VERSION "J35_6MT"

NS_ :

BS_:

BU_: PCM UNKNOWN VSA

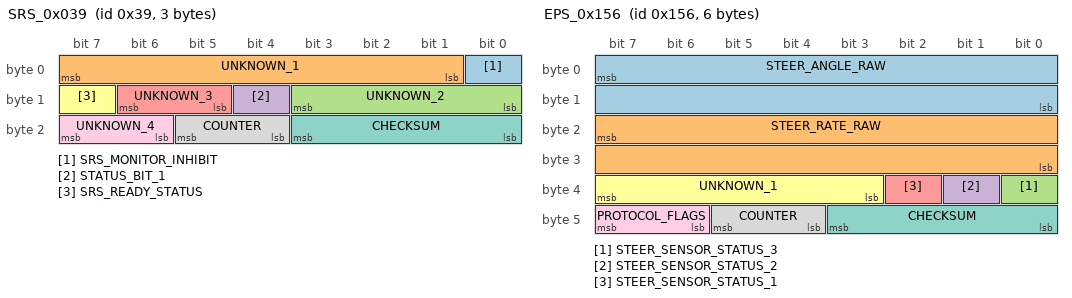
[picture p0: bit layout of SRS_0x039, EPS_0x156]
BO_ 57 SRS_0x039: 3 UNKNOWN
 SG_ SRS_MONITOR_INHIBIT : 0|1@1+ (1,0) [0|1] ""  PCM
 SG_ UNKNOWN_1 : 1|7@1+ (1,0) [0|127] ""  PCM
 SG_ UNKNOWN_2 : 8|4@1+ (1,0) [0|15] ""  PCM
 SG_ STATUS_BIT_1 : 12|1@1+ (1,0) [0|1] ""  PCM
 SG_ UNKNOWN_3 : 13|2@1+ (1,0) [0|3] ""  PCM
 SG_ SRS_READY_STATUS : 15|1@1+ (1,0) [0|1] ""  PCM
 SG_ CHECKSUM : 16|4@1+ (1,0) [0|15] ""  PCM
 SG_ COUNTER : 20|2@1+ (1,0) [0|3] ""  PCM
 SG_ UNKNOWN_4 : 22|2@1+ (1,0) [0|3] ""  PCM

BO_ 342 EPS_0x156: 6 UNKNOWN
 SG_ STEER_ANGLE_RAW : 7|16@0- (-0.1,0) [-3276.7000000000003|3276.8] "deg"  UNKNOWN
 SG_ STEER_RATE_RAW : 23|16@0- (-1,0) [-32767|32768] "deg/s"  UNKNOWN
 SG_ STEER_SENSOR_STATUS_3 : 32|1@1+ (1,0) [0|1] ""  UNKNOWN
 SG_ STEER_SENSOR_STATUS_2 : 33|1@1+ (1,0) [0|1] ""  UNKNOWN
 SG_ STEER_SENSOR_STATUS_1 : 34|1@1+ (1,0) [0|1] ""  UNKNOWN
 SG_ UNKNOWN_1 : 35|5@1+ (1,0) [0|31] ""  UNKNOWN
 SG_ CHECKSUM : 40|4@1+ (1,0) [0|15] ""  UNKNOWN
 SG_ COUNTER : 44|2@1+ (1,0) [0|3] ""  UNKNOWN
 SG_ PROTOCOL_FLAGS : 46|2@1+ (1,0) [0|3] ""  UNKNOWN

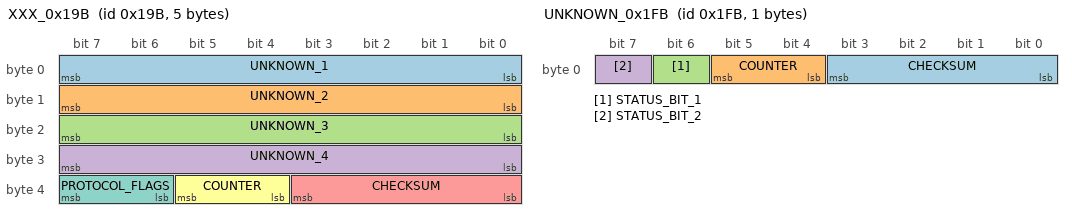
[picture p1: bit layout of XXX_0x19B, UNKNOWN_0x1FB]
BO_ 411 XXX_0x19B: 5 UNKNOWN
 SG_ UNKNOWN_1 : 0|8@1+ (1,0) [0|255] ""  UNKNOWN
 SG_ UNKNOWN_2 : 8|8@1+ (1,0) [0|255] ""  UNKNOWN
 SG_ UNKNOWN_3 : 16|8@1+ (1,0) [0|255] ""  UNKNOWN
 SG_ UNKNOWN_4 : 24|8@1+ (1,0) [0|255] ""  UNKNOWN
 SG_ CHECKSUM : 32|4@1+ (1,0) [0|15] ""  UNKNOWN
 SG_ COUNTER : 36|2@1+ (1,0) [0|3] ""  UNKNOWN
 SG_ PROTOCOL_FLAGS : 38|2@1+ (1,0) [0|3] ""  UNKNOWN

BO_ 506 UNKNOWN_0x1FA: 8 UNKNOWN
 SG_ BRAKE_COMMAND_RAW_TBD : 7|10@0+ (1,0) [0|1023] ""  VSA
 SG_ UNKNOWN_1 : 8|3@1+ (1,0) [0|7] ""  PCM
 SG_ UNKNOWN_2 : 11|2@1+ (1,0) [0|3] ""  PCM
 SG_ STATUS_BIT_1 : 13|1@1+ (1,0) [0|1] ""  PCM
 SG_ STATUS_BIT_2 : 16|1@1+ (1,0) [0|1] ""  PCM
 SG_ STATUS_BIT_3 : 17|1@1+ (1,0) [0|1] ""  PCM
 SG_ STATUS_BIT_4 : 18|1@1+ (1,0) [0|1] ""  PCM
 SG_ STATUS_BIT_5 : 19|1@1+ (1,0) [0|1] ""  PCM
 SG_ CRUISE_BRAKE_STATE_TBD : 20|2@1+ (1,0) [0|3] ""  PCM
 SG_ STATUS_BIT_6 : 22|1@1+ (1,0) [0|1] ""  PCM
 SG_ STATUS_BIT_7 : 23|1@1+ (1,0) [0|1] ""  PCM
 SG_ UNKNOWN_3 : 24|4@1+ (1,0) [0|15] ""  PCM
 SG_ STATUS_BIT_8 : 28|1@1+ (1,0) [0|1] ""  PCM
 SG_ STATUS_BIT_9 : 29|1@1+ (1,0) [0|1] ""  PCM
 SG_ STATUS_BIT_10 : 30|1@1+ (1,0) [0|1] ""  PCM
 SG_ STATUS_BIT_11 : 31|1@1+ (1,0) [0|1] ""  PCM
 SG_ CRUISE_STATUS_TBD : 32|3@1+ (1,0) [0|7] ""  PCM
 SG_ STATUS_BIT_12 : 35|1@1+ (1,0) [0|1] ""  PCM
 SG_ STATUS_BIT_13 : 36|1@1+ (1,0) [0|1] ""  PCM
 SG_ CRUISE_STATE_TBD : 37|2@1+ (1,0) [0|3] ""  PCM
 SG_ STATUS_BIT_14 : 39|1@1+ (1,0) [0|1] ""  PCM
 SG_ UNKNOWN_4 : 40|8@1+ (1,0) [0|255] ""  PCM
 SG_ UNKNOWN_5 : 55|10@0+ (1,0) [0|1023] ""  PCM
 SG_ CHECKSUM : 56|4@1+ (1,0) [0|15] ""  PCM
 SG_ COUNTER : 60|2@1+ (1,0) [0|3] ""  PCM

BO_ 507 UNKNOWN_0x1FB: 1 UNKNOWN
 SG_ CHECKSUM : 0|4@1+ (1,0) [0|15] ""  PCM
 SG_ COUNTER : 4|2@1+ (1,0) [0|3] ""  PCM
 SG_ STATUS_BIT_1 : 6|1@1+ (1,0) [0|1] ""  PCM
 SG_ STATUS_BIT_2 : 7|1@1+ (1,0) [0|1] ""  PCM

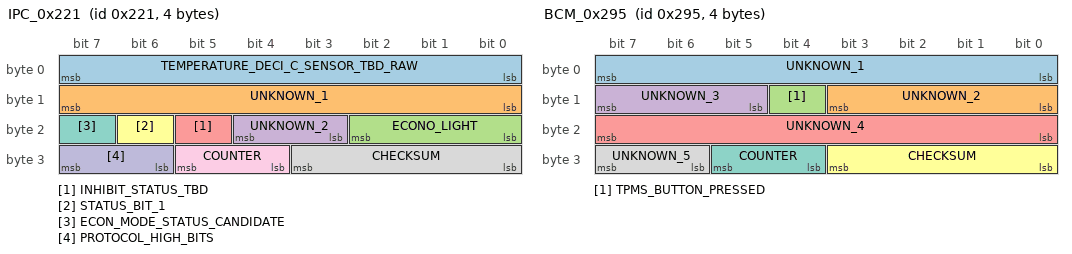
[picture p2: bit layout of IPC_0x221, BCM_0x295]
BO_ 545 IPC_0x221: 4 UNKNOWN
 SG_ TEMPERATURE_DECI_C_SENSOR_TBD_RAW : 0|8@1+ (1,-30) [-30|225] "degC"  PCM
 SG_ UNKNOWN_1 : 8|8@1+ (1,0) [0|255] ""  PCM
 SG_ ECONO_LIGHT : 16|3@1+ (1,0) [0|7] ""  PCM
 SG_ UNKNOWN_2 : 19|2@1+ (1,0) [0|3] ""  PCM
 SG_ INHIBIT_STATUS_TBD : 21|1@1+ (1,0) [0|1] ""  PCM
 SG_ STATUS_BIT_1 : 22|1@1+ (1,0) [0|1] ""  PCM
 SG_ ECON_MODE_STATUS_CANDIDATE : 23|1@1+ (1,0) [0|1] ""  PCM
 SG_ CHECKSUM : 24|4@1+ (1,0) [0|15] ""  PCM
 SG_ COUNTER : 28|2@1+ (1,0) [0|3] ""  PCM
 SG_ PROTOCOL_HIGH_BITS : 30|2@1+ (1,0) [0|3] ""  PCM
VAL_ 545 ECONO_LIGHT 0 "OFF" 3 "ON" ;

BO_ 661 BCM_0x295: 4 UNKNOWN
 SG_ UNKNOWN_1 : 0|8@1+ (1,0) [0|255] ""  UNKNOWN
 SG_ UNKNOWN_2 : 8|4@1+ (1,0) [0|15] ""  UNKNOWN
 SG_ TPMS_BUTTON_PRESSED : 12|1@1+ (1,0) [0|1] ""  UNKNOWN
 SG_ UNKNOWN_3 : 13|3@1+ (1,0) [0|7] ""  UNKNOWN
 SG_ UNKNOWN_4 : 16|8@1+ (1,0) [0|255] ""  UNKNOWN
 SG_ CHECKSUM : 24|4@1+ (1,0) [0|15] ""  UNKNOWN
 SG_ COUNTER : 28|2@1+ (1,0) [0|3] ""  UNKNOWN
 SG_ UNKNOWN_5 : 30|2@1+ (1,0) [0|3] ""  UNKNOWN

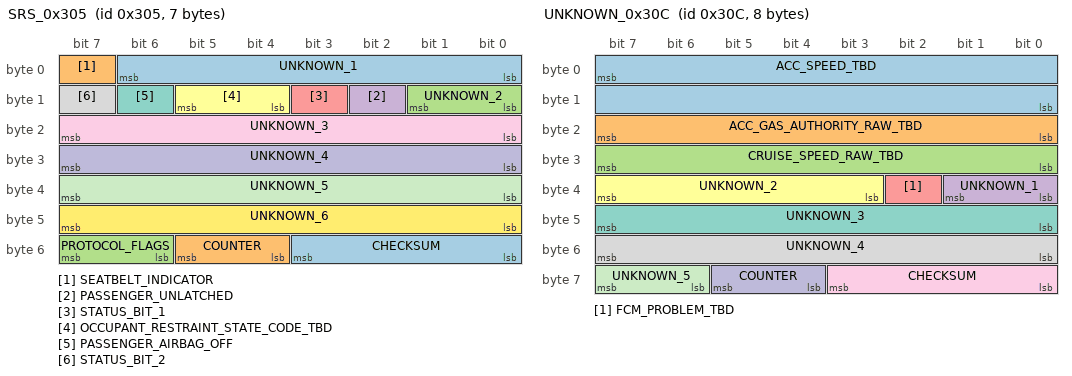
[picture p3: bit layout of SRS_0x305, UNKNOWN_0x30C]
BO_ 773 SRS_0x305: 7 UNKNOWN
 SG_ UNKNOWN_1 : 0|7@1+ (1,0) [0|127] ""  PCM
 SG_ SEATBELT_INDICATOR : 7|1@1+ (1,0) [0|1] ""  PCM
 SG_ UNKNOWN_2 : 8|2@1+ (1,0) [0|3] ""  PCM
 SG_ PASSENGER_UNLATCHED : 10|1@1+ (1,0) [0|1] ""  PCM
 SG_ STATUS_BIT_1 : 11|1@1+ (1,0) [0|1] ""  PCM
 SG_ OCCUPANT_RESTRAINT_STATE_CODE_TBD : 12|2@1+ (1,0) [0|0] ""  PCM
 SG_ PASSENGER_AIRBAG_OFF : 14|1@1+ (1,0) [0|1] ""  PCM
 SG_ STATUS_BIT_2 : 15|1@1+ (1,0) [0|1] ""  PCM
 SG_ UNKNOWN_3 : 16|8@1+ (1,0) [0|255] ""  PCM
 SG_ UNKNOWN_4 : 24|8@1+ (1,0) [0|255] ""  PCM
 SG_ UNKNOWN_5 : 32|8@1+ (1,0) [0|255] ""  PCM
 SG_ UNKNOWN_6 : 40|8@1+ (1,0) [0|255] ""  PCM
 SG_ CHECKSUM : 48|4@1+ (1,0) [0|15] ""  PCM
 SG_ COUNTER : 52|2@1+ (1,0) [0|3] ""  PCM
 SG_ PROTOCOL_FLAGS : 54|2@1+ (1,0) [0|3] ""  PCM

BO_ 780 UNKNOWN_0x30C: 8 UNKNOWN
 SG_ ACC_SPEED_TBD : 7|16@0+ (0.01,0) [0.0|655.35] "km/h"  PCM
 SG_ ACC_GAS_AUTHORITY_RAW_TBD : 16|8@1+ (5,0) [0|1275] ""  PCM
 SG_ CRUISE_SPEED_RAW_TBD : 24|8@1+ (1,0) [0|255] ""  PCM
 SG_ UNKNOWN_1 : 32|2@1+ (1,0) [0|3] ""  PCM
 SG_ FCM_PROBLEM_TBD : 34|1@1+ (1,0) [0|1] ""  PCM
 SG_ UNKNOWN_2 : 35|5@1+ (1,0) [0|31] ""  PCM
 SG_ UNKNOWN_3 : 40|8@1+ (1,0) [0|255] ""  PCM
 SG_ UNKNOWN_4 : 48|8@1+ (1,0) [0|255] ""  PCM
 SG_ CHECKSUM : 56|4@1+ (1,0) [0|15] ""  PCM
 SG_ COUNTER : 60|2@1+ (1,0) [0|3] ""  PCM
 SG_ UNKNOWN_5 : 62|2@1+ (1,0) [0|3] ""  PCM

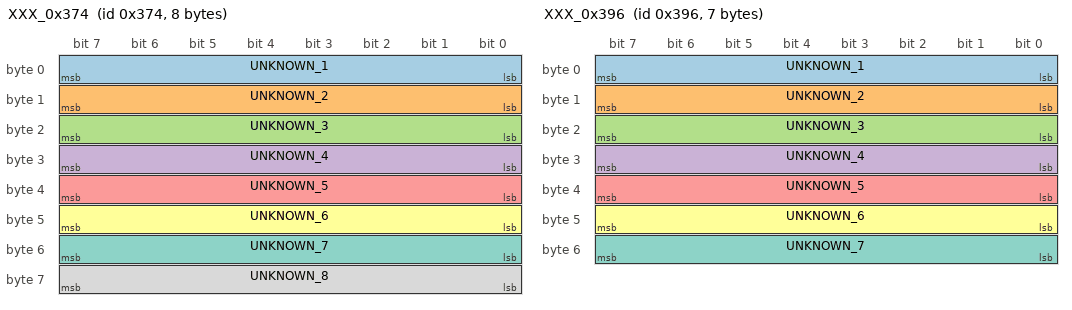
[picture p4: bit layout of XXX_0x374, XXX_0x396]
BO_ 884 XXX_0x374: 8 UNKNOWN
 SG_ UNKNOWN_1 : 0|8@1+ (1,0) [0|255] ""  UNKNOWN
 SG_ UNKNOWN_2 : 8|8@1+ (1,0) [0|255] ""  UNKNOWN
 SG_ UNKNOWN_3 : 16|8@1+ (1,0) [0|255] ""  UNKNOWN
 SG_ UNKNOWN_4 : 24|8@1+ (1,0) [0|255] ""  UNKNOWN
 SG_ UNKNOWN_5 : 32|8@1+ (1,0) [0|255] ""  UNKNOWN
 SG_ UNKNOWN_6 : 40|8@1+ (1,0) [0|255] ""  UNKNOWN
 SG_ UNKNOWN_7 : 48|8@1+ (1,0) [0|255] ""  UNKNOWN
 SG_ UNKNOWN_8 : 56|8@1+ (1,0) [0|255] ""  UNKNOWN

BO_ 918 XXX_0x396: 7 UNKNOWN
 SG_ UNKNOWN_1 : 0|8@1+ (1,0) [0|255] ""  UNKNOWN
 SG_ UNKNOWN_2 : 8|8@1+ (1,0) [0|255] ""  UNKNOWN
 SG_ UNKNOWN_3 : 16|8@1+ (1,0) [0|255] ""  UNKNOWN
 SG_ UNKNOWN_4 : 24|8@1+ (1,0) [0|255] ""  UNKNOWN
 SG_ UNKNOWN_5 : 32|8@1+ (1,0) [0|255] ""  UNKNOWN
 SG_ UNKNOWN_6 : 40|8@1+ (1,0) [0|255] ""  UNKNOWN
 SG_ UNKNOWN_7 : 48|8@1+ (1,0) [0|255] ""  UNKNOWN

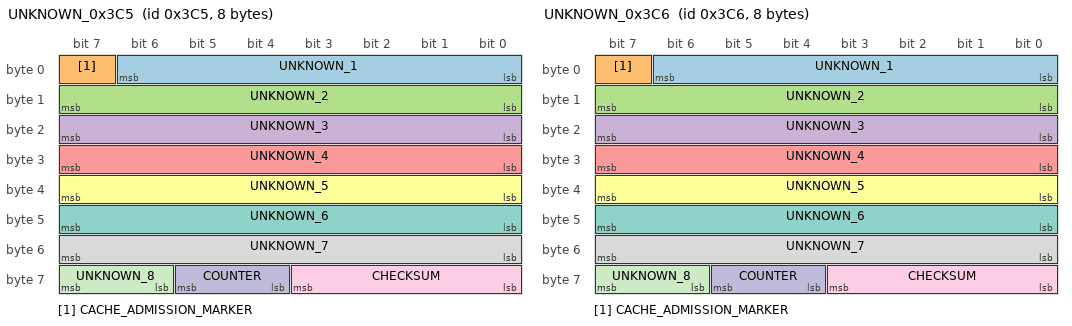
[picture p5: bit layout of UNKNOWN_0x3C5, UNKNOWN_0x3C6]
BO_ 965 UNKNOWN_0x3C5: 8 UNKNOWN
 SG_ UNKNOWN_1 : 0|7@1+ (1,0) [0|127] ""  PCM
 SG_ CACHE_ADMISSION_MARKER : 7|1@1+ (1,0) [0|1] ""  PCM
 SG_ UNKNOWN_2 : 8|8@1+ (1,0) [0|255] ""  PCM
 SG_ UNKNOWN_3 : 16|8@1+ (1,0) [0|255] ""  PCM
 SG_ UNKNOWN_4 : 24|8@1+ (1,0) [0|255] ""  PCM
 SG_ UNKNOWN_5 : 32|8@1+ (1,0) [0|255] ""  PCM
 SG_ UNKNOWN_6 : 40|8@1+ (1,0) [0|255] ""  PCM
 SG_ UNKNOWN_7 : 48|8@1+ (1,0) [0|255] ""  PCM
 SG_ CHECKSUM : 56|4@1+ (1,0) [0|15] ""  PCM
 SG_ COUNTER : 60|2@1+ (1,0) [0|3] ""  PCM
 SG_ UNKNOWN_8 : 62|2@1+ (1,0) [0|3] ""  PCM

BO_ 966 UNKNOWN_0x3C6: 8 UNKNOWN
 SG_ UNKNOWN_1 : 0|7@1+ (1,0) [0|127] ""  PCM
 SG_ CACHE_ADMISSION_MARKER : 7|1@1+ (1,0) [0|1] ""  PCM
 SG_ UNKNOWN_2 : 8|8@1+ (1,0) [0|255] ""  PCM
 SG_ UNKNOWN_3 : 16|8@1+ (1,0) [0|255] ""  PCM
 SG_ UNKNOWN_4 : 24|8@1+ (1,0) [0|255] ""  PCM
 SG_ UNKNOWN_5 : 32|8@1+ (1,0) [0|255] ""  PCM
 SG_ UNKNOWN_6 : 40|8@1+ (1,0) [0|255] ""  PCM
 SG_ UNKNOWN_7 : 48|8@1+ (1,0) [0|255] ""  PCM
 SG_ CHECKSUM : 56|4@1+ (1,0) [0|15] ""  PCM
 SG_ COUNTER : 60|2@1+ (1,0) [0|3] ""  PCM
 SG_ UNKNOWN_8 : 62|2@1+ (1,0) [0|3] ""  PCM

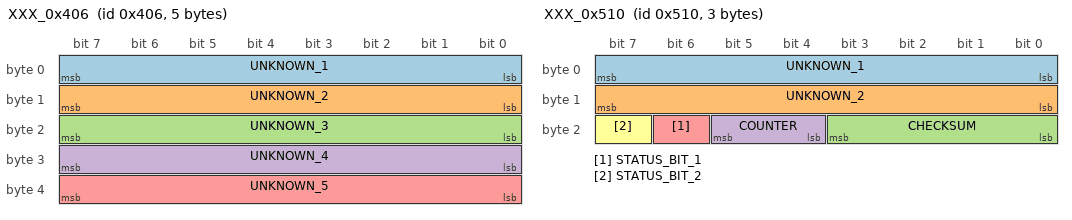
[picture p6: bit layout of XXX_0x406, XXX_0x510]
BO_ 1030 XXX_0x406: 5 UNKNOWN
 SG_ UNKNOWN_1 : 0|8@1+ (1,0) [0|255] ""  UNKNOWN
 SG_ UNKNOWN_2 : 8|8@1+ (1,0) [0|255] ""  UNKNOWN
 SG_ UNKNOWN_3 : 16|8@1+ (1,0) [0|255] ""  UNKNOWN
 SG_ UNKNOWN_4 : 24|8@1+ (1,0) [0|255] ""  UNKNOWN
 SG_ UNKNOWN_5 : 32|8@1+ (1,0) [0|255] ""  UNKNOWN

BO_ 1296 XXX_0x510: 3 UNKNOWN
 SG_ UNKNOWN_1 : 0|8@1+ (1,0) [0|255] ""  PCM
 SG_ UNKNOWN_2 : 8|8@1+ (1,0) [0|255] ""  PCM
 SG_ CHECKSUM : 16|4@1+ (1,0) [0|15] ""  PCM
 SG_ COUNTER : 20|2@1+ (1,0) [0|3] ""  PCM
 SG_ STATUS_BIT_1 : 22|1@1+ (1,0) [0|1] ""  PCM
 SG_ STATUS_BIT_2 : 23|1@1+ (1,0) [0|1] ""  PCM

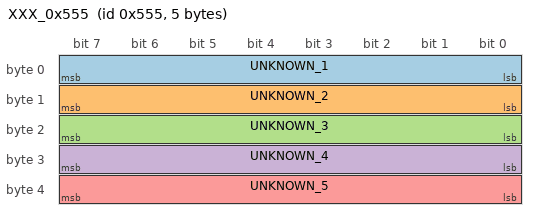
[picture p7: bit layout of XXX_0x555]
BO_ 1365 XXX_0x555: 5 UNKNOWN
 SG_ UNKNOWN_1 : 0|8@1+ (1,0) [0|255] ""  UNKNOWN
 SG_ UNKNOWN_2 : 8|8@1+ (1,0) [0|255] ""  UNKNOWN
 SG_ UNKNOWN_3 : 16|8@1+ (1,0) [0|255] ""  UNKNOWN
 SG_ UNKNOWN_4 : 24|8@1+ (1,0) [0|255] ""  UNKNOWN
 SG_ UNKNOWN_5 : 32|8@1+ (1,0) [0|255] ""  UNKNOWN
